AUTOSAR XML (schema 00048)
package /ARRoot/ApplicationDataType
  app type apdt_direction_indicator_flashes: category=VALUE
package /ARRoot/SwComponents/PortInterfaces
  client server interface csi_direction_indicator_control
    operation cso_turn_off
    operation cso_turn_on
  sender receiver interface sri_direction_indicator_turned_on
    data vdp_indicator_flashes: type=apdt_direction_indicator_flashes
package /ARRoot/SwComponents/SwComponentTypes/AtomicSwComponentTypes
  application sw component type aswct_direction_actuator
    provide port ppp_direction_actuator: provided-interface=csi_direction_indicator_control
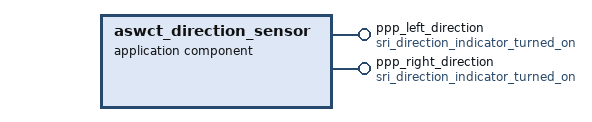
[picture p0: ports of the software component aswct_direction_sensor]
  application sw component type aswct_direction_sensor
    provide port ppp_left_direction: provided-interface=sri_direction_indicator_turned_on
    provide port ppp_right_direction: provided-interface=sri_direction_indicator_turned_on
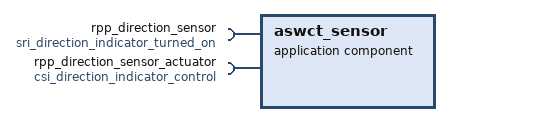
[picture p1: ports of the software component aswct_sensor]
  application sw component type aswct_sensor
    require port rpp_direction_sensor: required-interface=sri_direction_indicator_turned_on
    require port rpp_direction_sensor_actuator: required-interface=csi_direction_indicator_control
package /ARRoot/SwComponents/SwComponentTypes/CompositionSwComponentTypes
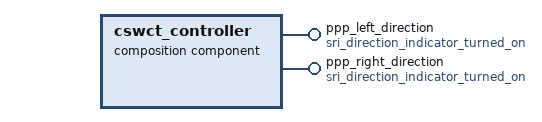
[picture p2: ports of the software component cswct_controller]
  composition sw component type cswct_controller
    provide port ppp_left_direction: provided-interface=sri_direction_indicator_turned_on
    provide port ppp_right_direction: provided-interface=sri_direction_indicator_turned_on
    component scp_2_aswct_direction_sensor: type=aswct_direction_sensor
    delegate scp_2_aswct_direction_sensor.ppp_left_direction <-> outer port aswct_direction_sensor/ppp_left_direction
    delegate scp_2_aswct_direction_sensor.ppp_right_direction <-> outer port aswct_direction_sensor/ppp_right_direction
  composition sw component type cswct_direction_indicator
    require port rpp_direction_sensor: required-interface=sri_direction_indicator_turned_on
    component scp_1_aswct_sensor: type=aswct_sensor
    component scp_3_aswct_direction_actuator: type=aswct_direction_actuator
    connect scp_3_aswct_direction_actuator.ppp_direction_actuator -> scp_1_aswct_sensor.rpp_direction_sensor_actuator
    delegate scp_1_aswct_sensor.rpp_direction_sensor <-> outer port cswct_direction_indicator/rpp_direction_sensor
